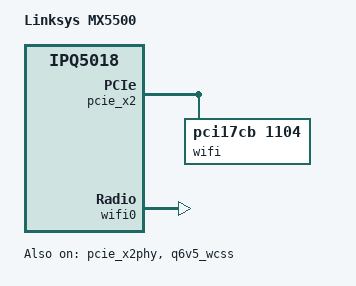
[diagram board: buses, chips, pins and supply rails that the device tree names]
/dts-v1/;

#include "ipq5018.dtsi"
#include "ipq5018-mx-atlas6.dtsi"

#include <dt-bindings/gpio/gpio.h>
#include <dt-bindings/input/input.h>
#include <dt-bindings/leds/common.h>

/ {
	model = "Linksys MX5500";
	compatible = "linksys,mx5500", "qcom,ipq5018";
};

&pcie_x2phy {
	status = "okay";
};

&pcie_x2 {
	status = "okay";

	perst-gpios = <&tlmm 15 GPIO_ACTIVE_LOW>;

	bridge@0,0 {
		reg = <0x00000000 0 0 0 0>;
		#address-cells = <3>;
		#size-cells = <2>;
		ranges;

		wifi@1,0 {
			status = "okay";

			/* QCN9074: ath11k lacks DT compatible for PCI cards */
			compatible = "pci17cb,1104";
			reg = <0x00010000 0 0 0 0>;

			qcom,ath11k-calibration-variant = "Linksys-MX5500";
		};
	};
};

&q6v5_wcss {
	status = "okay";

	memory-region = <&q6_mem_regions>;
	firmware-name = "ath11k/IPQ5018/hw1.0/q6_fw.mdt",
					"ath11k/IPQ5018/hw1.0/m3_fw.mdt";

	// IPQ5018
	q6_wcss_pd1: pd-1 {
		firmware-name = "ath11k/IPQ5018/hw1.0/q6_fw.mdt";

		resets =
			<&gcc GCC_WCSSAON_RESET>,
			<&gcc GCC_WCSS_BCR>,
			<&gcc GCC_CE_BCR>;
		reset-names =
			"wcss_aon_reset",
			"wcss_reset",
			"ce_reset";

		clocks =
			<&gcc GCC_WCSS_AHB_S_CLK>,
			<&gcc GCC_WCSS_ACMT_CLK>,
			<&gcc GCC_WCSS_AXI_M_CLK>;
		clock-names =
			"gcc_wcss_ahb_s_clk",
			"gcc_wcss_acmt_clk",
			"gcc_wcss_axi_m_clk";

		interrupts-extended =
			<&wcss_smp2p_in 8 0>,
			<&wcss_smp2p_in 9 0>,
			<&wcss_smp2p_in 12 0>,
			<&wcss_smp2p_in 11 0>;
		interrupt-names =
			"fatal",
			"ready",
			"spawn-ack",
			"stop-ack";

		qcom,smem-states =
			<&wcss_smp2p_out 8>,
			<&wcss_smp2p_out 9>,
			<&wcss_smp2p_out 10>;
		qcom,smem-state-names =
			"shutdown",
			"stop",
			"spawn";
		status = "okay";
	};
};

&wifi0 {
	// IPQ5018
	qcom,rproc = <&q6_wcss_pd1>;
	qcom,ath11k-calibration-variant = "Linksys-MX5500";
	qcom,ath11k-fw-memory-mode = <2>;
	qcom,bdf-addr = <0x4c400000>;

	status = "okay";
};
